# MCU_CPT2_AGGR0_MMR register map
Vendor: Texas Instruments
Peripheral module from a debugger description file (folder am62P).
Registers are 32-bit, access per field, reset values left out (the file's numbers can be read two ways) unless marked. A register's access mark holds for its fields unless they carry their own. Offsets are as the file gives them; lines under a group give offsets from that group; [hi:lo] are bit positions; {n}, {i} and the like mark numbered series; 'fields as' and 'values as' point back to an identical list; <NAME> marks a mode.

## MCU_CPT2_AGGR0_MMR
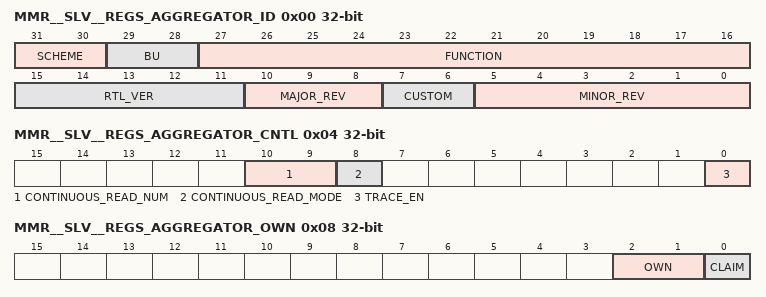
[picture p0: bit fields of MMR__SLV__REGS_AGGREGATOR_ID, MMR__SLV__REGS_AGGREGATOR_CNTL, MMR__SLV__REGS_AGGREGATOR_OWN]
0x00 MMR__SLV__REGS_AGGREGATOR_ID ro — This is the standard TI peripheral ID register that exists at address 0 in the preipheral space
  [31:30] SCHEME, [29:28] BU, [27:16] FUNCTION, [15:11] RTL_VER, [10:8] MAJOR_REV, [7:6] CUSTOM, [5:0] MINOR_REV
0x04 MMR__SLV__REGS_AGGREGATOR_CNTL — This register contains the controls for serial indrect access and trace processing
  [10:9] CONTINUOUS_READ_NUM rw, [8] CONTINUOUS_READ_MODE rw, [0] TRACE_EN rw
0x08 MMR__SLV__REGS_AGGREGATOR_OWN — Module Ownership Control and Status Register
  [2:1] OWN ro, [0] CLAIM rw
{0x20+0x10*i} MMR__SLV__REGS_CONT_READ_PORT{i} (i=0..3) — Designates which port (peripheral) is the target of this port, address, data register group
  [4:0] PORT rw
{0x24+0x10*i} MMR__SLV__REGS_CONT_READ_ADDR{i} (i=0..3) — Designates the offest (in peripheral space) that is the target of this port, address, data register group
  [15:0] ADDR rw
{0x28+0x10*i} MMR__SLV__REGS_CONT_READ_DATA{i} ro (i=0..3) — Provides the continuous read data for this port, address, data register group
  [31:0] DATA
